# H5 register map
Vendor: Allwinner; Series: H5; File version: 0.1
CPU: 0, little endian, MPU, no FPU, 0 interrupt priority bits
Registers are 32-bit, read-write, reset 0x0 unless marked. A register's access mark holds for its fields unless they carry their own. Offsets are from the block's base; lines under a group give offsets from that group; [hi:lo] are bit positions; {n}, {i} and the like mark numbered series; 'fields as' and 'values as' point back to an identical list; <NAME> marks a mode.

## Memory map
0x01700000 CPU_CFG
0x01C00000 System_Control
0x01C02000 DMA
0x01C03000 NDFC
0x01C06000 TSC
0x01C06040 TSG
0x01C06100 TSF0
0x01C06180 TSD0
0x01C06200 TSF1
0x01C06280 TSD1
0x01C06300 TSF2
0x01C06380 TSD2
0x01C06400 TSF3
0x01C06480 TSD3
0x01C06500 TSF4
0x01C06580 TSD4
0x01C0C000 TCON0
0x01C0D000 TCON1
0x01C0F000 SMHC0
0x01C10000 SMHC1
0x01C11000 SMHC2
0x01C15000 CE_NS
0x01C15800 CE_S
0x01C17000 MSGBOX
0x01C18000 SPINLOCK
0x01C1B000 USB_HCI1
0x01C1C000 USB_HCI2
0x01C1D000 USB_HCI3
0x01C1E000 SMC
0x01C20000 CCU
0x01C20800 PIO
0x01C20C00 TIMER
0x01C21000 OWA
0x01C21400 PWM
0x01C21800 KEYADC
0x01C22000 I2S/PCM_0
0x01C22400 I2S/PCM_1
0x01C22800 I2S/PCM_2
0x01C22C00 Audio_Codec
0x01C23400 SPC
0x01C25000 Thermal_Sensor
0x01C28000 UART0
0x01C28400 UART1
0x01C28800 UART2
0x01C28C00 UART3
0x01C2AC00 TWI0
0x01C2B000 TWI1
0x01C2B400 TWI2
0x01C2C400 SCR0
0x01C2C800 SCR1
0x01C30000 EMAC
0x01C60000 High_Speed_Timer
0x01C68000 SPI0
0x01C69000 SPI1
0x01CB0000 CSI0
0x01F00000 RTC
0x01F01800 TWD
0x01F02000 CIR
0x01F02400 R_TWI
0x01F02800 R-UART
0x01F02C00 PIO

## CE_NS
Base 0x01C15000
Same registers: CE_S 0x01C15800
0x00 CE_TDA
  [31:0] CE_TDA — Task Descriptor Address
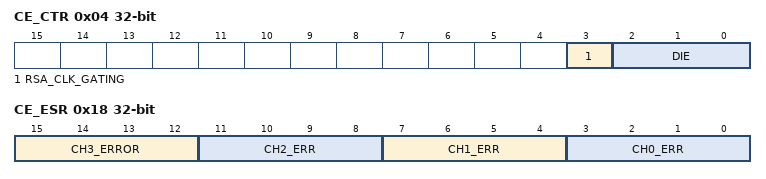
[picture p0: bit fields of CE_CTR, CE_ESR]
0x04 CE_CTR (reset mask 0x8) — Gating Control Register
  [3] RSA_CLK_GATING — RSA CLK Gating Enable(only for S world) 0: RSA clk gating enable 1: RSA clk gating disable
    0=enable (RSA clk gating enable); 1=disable (RSA clk gating disable)
  [2:0] DIE ro — Die Bonding ID
0x08 CE_ICR — Interrupt Control Register
  [3:0] TASK_INT_EN — Task chaining0~3 interrupt enable 0: Interrupt disable 1: Interrupt enable
0x0C CE_ISR — Interrupt Status Register
  [3:0] TASK_END_PENDING write-1-clears — Task channel0-3 end pending 0: Not finished 1: Finished It indicates whether task has been completed . Note: W ite to lea it.
0x10 CE_TLR — Task Load Register
  [0] TASK_LOAD — When set , CE starts to load the configure of task from task descriptor queue and start to perform the task if task FIFO is not full.
0x14 CE_TSR
  [1:0] TASK_CHANNEL ro — Indicate which channel is running 00: Task channel0 01: Task channel1 10: Task channel2 11: Task channel3
0x18 CE_ESR — Task Error type Register
  [all] fields
    1=Algorithm not support; 2=Data length error; 4=Keysram access error for AES
  [15:12] CH3_ERROR write-1-clears — Task channel3 error type xxx1: Algorithm not support xx1x: Data length error x1xx: Keysram access error for AES 1xxx: Reserved Write 1 to clear it.
  [11:8] CH2_ERR write-1-clears — Task channel2 error type xxx1: Algorithm not support xx1x: Data length error x1xx: Keysram access error for AES 1xxx: Reserved Write 1 to clear it.
  [7:4] CH1_ERR write-1-clears — Task channel1 error type xxx1: Algorithm not support xx1x: Data length error x1xx: Keysram access error for AES 1xxx: Reserved Write 1 to clear it.
  [3:0] CH0_ERR write-1-clears — Task channel0 error type xxx1: Algorithm not support xx1x: Data length error x1xx: Keysram access error for AES 1xxx: Reserved Write 1 to clear it.
0x24 CE_CSAR — Current Source Address Register
  [31:0] SRC_ADR ro — Current source address of the executing task
0x28 CE_CDAR — Current Destination Address Register
  [31:0] DES_ADR ro — Current destination address of the executing task
0x2C CE_TPR — Throughput Register
  [31:0] THROUGHPUT — It indicates the throughput of data from the whole processing. W ite 0 to lea it by CPU.

## System_Control
Base 0x01C00000
0x24 VER_REG (reset mask 0xFF) — Version Register
  [8] UBOOT_SEL_PAD_STA ro — U_boot Select Pin Status. 0: U_Boot 1: Normal Boot
    0=U_Boot; 1=Normal Boot
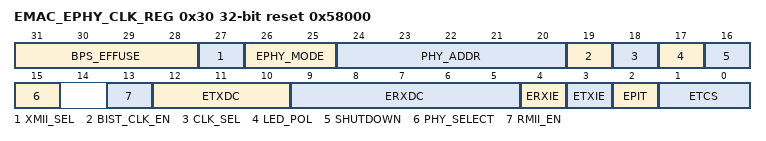
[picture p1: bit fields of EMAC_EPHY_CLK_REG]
0x30 EMAC_EPHY_CLK_REG reset 0x58000 — EMAC-EPHY Clock Register
  [31:28] BPS_EFFUSE
  [27] XMII_SEL — 0: Internal SMI and MII 1: External SMI and MII
    0=Internal SMI and MII; 1=External SMI and MII
  [26:25] EPHY_MODE — Operation Mode Selection 00: Normal Mode 01: Sim Mode 10: AFE Test Mode 11: /
    0=Normal Mode; 1=Sim (Sim Mode); 2=AFE (AFE Test Mode)
  [24:20] PHY_ADDR — PHY Address
  [19] BIST_CLK_EN — 0: BIST clk disable 1: BIST clk enable
    0=BIST_clk_disable; 1=BIST_clk_enable
  [18] CLK_SEL — 0: 25MHz 1: 24MHz
    0=_25MHz; 1=_24MHz
  [17] LED_POL — 0: High active 1: Low active
    0=High active; 1=Low (Low active)
  [16] SHUTDOWN — 0: Power up 1: Shutdown
    0=Power up; 1=Shutdown
  [15] PHY_SELECT — 0: External PHY 1: Internal PHY
    0=External PHY; 1=Internal PHY
  [13] RMII_EN — 0: Disable RMII Module 1: Enable RMII Module When this bit assert, MII or RGMII interface is disabled( This means bit13 is prior to bit2)
    0=Disable RMII Module; 1=Enable RMII Module When this bit assert, MII or RGMII interface is disabled( This means bit13 is prior to bit2)
  [12:10] ETXDC — Configure EMAC Transmit Clock Delay Chain.
  [9:5] ERXDC — Configure EMAC Receive Clock Delay Chain.
  [4] ERXIE — Enable EMAC Receive Clock Invertor. 0: Disable 1: Enable
    0=Disable; 1=Enable
  [3] ETXIE — Enable EMAC Transmit Clock Invertor. 0: Disable 1: Enable
    0=Disable; 1=Enable
  [2] EPIT — EMAC PHY Interface Type 0: MII 1: RGMII
    0=MII; 1=RGMII
  [1:0] ETCS — EMAC Transmit Clock Source 00: Transmit clock source for MII 01: External transmit clock source for GMII and RGMII 10: Internal transmit clock source for GMII and RGMII 11: Reserved
    0=Transmit clock source for MII; 1=External transmit clock source for GMII and RGMII; 2=Internal transmit clock source for GMII and RGMII

## Licence text in the file
questionable
